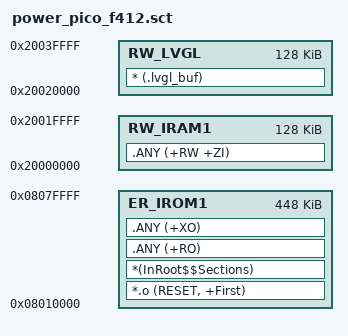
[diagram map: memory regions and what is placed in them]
; Keep the application stack and ordinary data in the tested lower 128 KiB.
LR_IROM1 0x08010000 0x00070000 {
  ER_IROM1 0x08010000 0x00070000 {
    *.o (RESET, +First)
    *(InRoot$$Sections)
    .ANY (+RO)
    .ANY (+XO)
  }
  RW_IRAM1 0x20000000 0x00020000 {
    .ANY (+RW +ZI)
  }
  RW_LVGL 0x20020000 0x00020000 {
    * (.lvgl_buf)
  }
}
